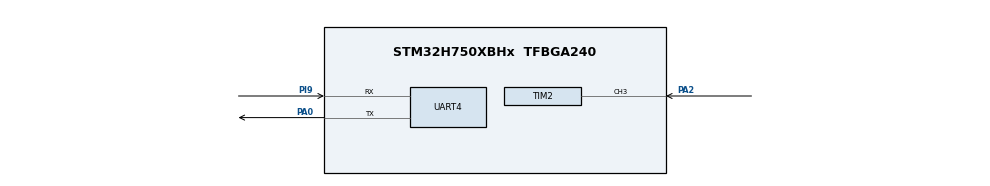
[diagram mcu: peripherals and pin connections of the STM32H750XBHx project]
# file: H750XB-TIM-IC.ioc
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CORTEX_M7.AccessPermission-Cortex_Memory_Protection_Unit_Region0_Settings=MPU_REGION_FULL_ACCESS
CORTEX_M7.BaseAddress-Cortex_Memory_Protection_Unit_Region0_Settings=0x24000000
CORTEX_M7.CPU_DCache=Enabled
CORTEX_M7.CPU_ICache=Enabled
CORTEX_M7.Enable-Cortex_Memory_Protection_Unit_Region0_Settings=MPU_REGION_ENABLE
CORTEX_M7.IsCacheable-Cortex_Memory_Protection_Unit_Region0_Settings=MPU_ACCESS_CACHEABLE
CORTEX_M7.MPU_Control=MPU_PRIVILEGED_DEFAULT
Mcu.Family=STM32H7
Mcu.Name=STM32H750XBHx
Mcu.Package=TFBGA240
NVIC.PriorityGroup=NVIC_PRIORITYGROUP_4
NVIC.TIM2_IRQn=true\:0\:0\:false\:false\:true\:true\:true
PA0.Mode=Asynchronous
PA0.Signal=UART4_TX
PA2.GPIO_Speed=GPIO_SPEED_FREQ_LOW
PA2.Signal=S_TIM2_CH3
PH0-OSC_IN\ (PH0).Mode=HSE-External-Oscillator
PH0-OSC_IN\ (PH0).Signal=RCC_OSC_IN
PH1-OSC_OUT\ (PH1).Mode=HSE-External-Oscillator
PH1-OSC_OUT\ (PH1).Signal=RCC_OSC_OUT
PI9.Mode=Asynchronous
PI9.Signal=UART4_RX
ProjectManager.HeapSize=0x1000
ProjectManager.StackSize=0x1000
ProjectManager.TargetToolchain=MDK-ARM V5.27
RCC.ADCFreq_Value=50390625
RCC.APB1Freq_Value=120000000
RCC.APB2Freq_Value=120000000
RCC.APB3Freq_Value=120000000
RCC.APB4Freq_Value=120000000
RCC.CortexFreq_Value=480000000
RCC.D1PPRE=RCC_APB3_DIV2
RCC.D2PPRE1=RCC_APB1_DIV2
RCC.D2PPRE2=RCC_APB2_DIV2
RCC.D3PPRE=RCC_APB4_DIV2
RCC.DIVM1=5
RCC.DIVM3=5
RCC.DIVN1=192
RCC.DIVN3=192
RCC.DIVQ3=16
RCC.HCLKFreq_Value=240000000
RCC.HPRE=RCC_HCLK_DIV2
RCC.PLLSourceVirtual=RCC_PLLSOURCE_HSE
RCC.SYSCLKFreq_VALUE=480000000
RCC.SYSCLKSource=RCC_SYSCLKSOURCE_PLLCLK
RCC.USART234578CLockSelection=RCC_USART234578CLKSOURCE_PLL3
RCC.USBFreq_Value=480000000
SH.S_TIM2_CH3.0=TIM2_CH3,Input_Capture3_from_TI3
TIM2.Channel-Input_Capture3_from_TI3=TIM_CHANNEL_3
TIM2.Period=0xFFFFFFFF
VP_TIM2_VS_ClockSourceINT.Mode=Internal
board=custom

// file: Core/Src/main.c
/* USER CODE BEGIN Header */
/**
  ******************************************************************************
  * @file           : main.c
  * @brief          : Main program body
  ******************************************************************************
  * @attention
  *
  * <h2><center>&copy; Copyright (c) 2021 STMicroelectronics.
  * All rights reserved.</center></h2>
  *
  * This software component is licensed by ST under BSD 3-Clause license,
  * the "License"; You may not use this file except in compliance with the
  * License. You may obtain a copy of the License at:
  *                        opensource.org/licenses/BSD-3-Clause
  *
  ******************************************************************************
  */
/* USER CODE END Header */
#include "main.h"
#include "tim.h"
#include "usart.h"
#include "gpio.h"

void SystemClock_Config(void);
static void MPU_Config(void);

int main(void)
{
  /* USER CODE BEGIN 1 */
	double frequency;
  /* USER CODE END 1 */

  /* MPU Configuration--------------------------------------------------------*/
  MPU_Config();

  /* Enable I-Cache---------------------------------------------------------*/
  SCB_EnableICache();

  /* Enable D-Cache---------------------------------------------------------*/
  SCB_EnableDCache();

  /* MCU Configuration--------------------------------------------------------*/

  /* Reset of all peripherals, Initializes the Flash interface and the Systick. */
  HAL_Init();

  /* Configure the system clock */
  SystemClock_Config();

  /* Initialize all configured peripherals */
  MX_GPIO_Init();
  MX_TIM2_Init();
  MX_UART4_Init();

  /* Infinite loop */
  /* USER CODE BEGIN WHILE */
  while (1)
  {
		frequency = TIM_IC_Frequency();
		printf("frequency = %0.4lf\r\n", frequency);
		HAL_Delay(500);
    /* USER CODE END WHILE */

  }
}

void SystemClock_Config(void)
{
  RCC_OscInitTypeDef RCC_OscInitStruct = {0};
  RCC_ClkInitTypeDef RCC_ClkInitStruct = {0};

  /** Supply configuration update enable
  */
  HAL_PWREx_ConfigSupply(PWR_LDO_SUPPLY);
  /** Configure the main internal regulator output voltage
  */
  __HAL_PWR_VOLTAGESCALING_CONFIG(PWR_REGULATOR_VOLTAGE_SCALE0);

  while(!__HAL_PWR_GET_FLAG(PWR_FLAG_VOSRDY)) {}
  /** Macro to configure the PLL clock source
  */
  __HAL_RCC_PLL_PLLSOURCE_CONFIG(RCC_PLLSOURCE_HSE);
  /** Initializes the RCC Oscillators according to the specified parameters
  * in the RCC_OscInitTypeDef structure.
  */
  RCC_OscInitStruct.OscillatorType = RCC_OSCILLATORTYPE_HSE;
  RCC_OscInitStruct.HSEState = RCC_HSE_ON;
  RCC_OscInitStruct.PLL.PLLState = RCC_PLL_ON;
  RCC_OscInitStruct.PLL.PLLSource = RCC_PLLSOURCE_HSE;
  RCC_OscInitStruct.PLL.PLLM = 5;
  RCC_OscInitStruct.PLL.PLLN = 192;
  RCC_OscInitStruct.PLL.PLLP = 2;
  RCC_OscInitStruct.PLL.PLLQ = 2;
  RCC_OscInitStruct.PLL.PLLR = 2;
  RCC_OscInitStruct.PLL.PLLRGE = RCC_PLL1VCIRANGE_2;
  RCC_OscInitStruct.PLL.PLLVCOSEL = RCC_PLL1VCOWIDE;
  RCC_OscInitStruct.PLL.PLLFRACN = 0;
  if (HAL_RCC_OscConfig(&RCC_OscInitStruct) != HAL_OK)
  {
    Error_Handler();
  }
  /** Initializes the CPU, AHB and APB buses clocks
  */
  RCC_ClkInitStruct.ClockType = RCC_CLOCKTYPE_HCLK|RCC_CLOCKTYPE_SYSCLK
                              |RCC_CLOCKTYPE_PCLK1|RCC_CLOCKTYPE_PCLK2
                              |RCC_CLOCKTYPE_D3PCLK1|RCC_CLOCKTYPE_D1PCLK1;
  RCC_ClkInitStruct.SYSCLKSource = RCC_SYSCLKSOURCE_PLLCLK;
  RCC_ClkInitStruct.SYSCLKDivider = RCC_SYSCLK_DIV1;
  RCC_ClkInitStruct.AHBCLKDivider = RCC_HCLK_DIV2;
  RCC_ClkInitStruct.APB3CLKDivider = RCC_APB3_DIV2;
  RCC_ClkInitStruct.APB1CLKDivider = RCC_APB1_DIV2;
  RCC_ClkInitStruct.APB2CLKDivider = RCC_APB2_DIV2;
  RCC_ClkInitStruct.APB4CLKDivider = RCC_APB4_DIV2;

  if (HAL_RCC_ClockConfig(&RCC_ClkInitStruct, FLASH_LATENCY_4) != HAL_OK)
  {
    Error_Handler();
  }
}

/* MPU Configuration */

void MPU_Config(void)
{
  MPU_Region_InitTypeDef MPU_InitStruct = {0};

  /* Disables the MPU */
  HAL_MPU_Disable();
  /** Initializes and configures the Region and the memory to be protected
  */
  MPU_InitStruct.Enable = MPU_REGION_ENABLE;
  MPU_InitStruct.Number = MPU_REGION_NUMBER0;
  MPU_InitStruct.BaseAddress = 0x24000000;
  MPU_InitStruct.Size = MPU_REGION_SIZE_32B;
  MPU_InitStruct.SubRegionDisable = 0x0;
  MPU_InitStruct.TypeExtField = MPU_TEX_LEVEL0;
  MPU_InitStruct.AccessPermission = MPU_REGION_FULL_ACCESS;
  MPU_InitStruct.DisableExec = MPU_INSTRUCTION_ACCESS_ENABLE;
  MPU_InitStruct.IsShareable = MPU_ACCESS_NOT_SHAREABLE;
  MPU_InitStruct.IsCacheable = MPU_ACCESS_CACHEABLE;
  MPU_InitStruct.IsBufferable = MPU_ACCESS_NOT_BUFFERABLE;

  HAL_MPU_ConfigRegion(&MPU_InitStruct);
  /* Enables the MPU */
  HAL_MPU_Enable(MPU_PRIVILEGED_DEFAULT);

}

void Error_Handler(void)
{
  __disable_irq();
  while (1)
  {
  }
}

/************************ (C) COPYRIGHT STMicroelectronics *****END OF FILE****/
